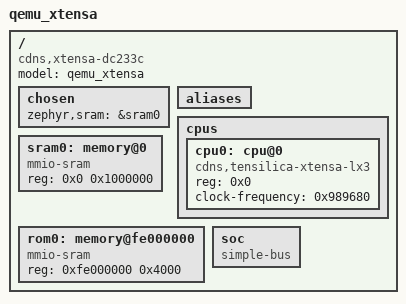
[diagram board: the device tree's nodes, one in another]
/dts-v1/;

/* node '/' defined in zephyr/dts/common/skeleton.dtsi:9 */
/ {
	#address-cells = < 0x1 >;          /* in zephyr/dts/common/skeleton.dtsi:10 */
	#size-cells = < 0x1 >;             /* in zephyr/dts/common/skeleton.dtsi:11 */
	model = "qemu_xtensa";             /* in zephyr/boards/qemu/xtensa/qemu_xtensa_dc233c.dts:12 */
	compatible = "cdns,xtensa-dc233c"; /* in zephyr/boards/qemu/xtensa/qemu_xtensa_dc233c.dts:13 */

	/* node '/chosen' defined in zephyr/dts/common/skeleton.dtsi:13 */
	chosen {
		zephyr,sram = &sram0; /* in zephyr/boards/qemu/xtensa/qemu_xtensa_dc233c.dts:16 */
	};

	/* node '/aliases' defined in zephyr/dts/common/skeleton.dtsi:15 */
	aliases {
	};

	/* node '/cpus' defined in zephyr/dts/xtensa/dc233c.dtsi:10 */
	cpus {
		#address-cells = < 0x1 >; /* in zephyr/dts/xtensa/dc233c.dtsi:11 */
		#size-cells = < 0x0 >;    /* in zephyr/dts/xtensa/dc233c.dtsi:12 */

		/* node '/cpus/cpu@0' defined in zephyr/dts/xtensa/dc233c.dtsi:14 */
		cpu0: cpu@0 {
			device_type = "cpu";                      /* in zephyr/dts/xtensa/dc233c.dtsi:15 */
			compatible = "cdns,tensilica-xtensa-lx3"; /* in zephyr/dts/xtensa/dc233c.dtsi:16 */
			reg = < 0x0 >;                            /* in zephyr/dts/xtensa/dc233c.dtsi:17 */
			clock-frequency = < 0x989680 >;           /* in zephyr/boards/qemu/xtensa/qemu_xtensa_dc233c.dts:21 */
		};
	};

	/* node '/memory@0' defined in zephyr/dts/xtensa/dc233c.dtsi:25 */
	sram0: memory@0 {
		device_type = "memory";   /* in zephyr/dts/xtensa/dc233c.dtsi:26 */
		compatible = "mmio-sram"; /* in zephyr/dts/xtensa/dc233c.dtsi:27 */
		reg = < 0x0 0x1000000 >;  /* in zephyr/dts/xtensa/dc233c.dtsi:28 */
	};

	/* node '/memory@fe000000' defined in zephyr/dts/xtensa/dc233c.dtsi:35 */
	rom0: memory@fe000000 {
		device_type = "memory";      /* in zephyr/dts/xtensa/dc233c.dtsi:36 */
		compatible = "mmio-sram";    /* in zephyr/dts/xtensa/dc233c.dtsi:37 */
		reg = < 0xfe000000 0x4000 >; /* in zephyr/dts/xtensa/dc233c.dtsi:38 */
	};

	/* node '/soc' defined in zephyr/dts/xtensa/dc233c.dtsi:41 */
	soc {
		#address-cells = < 0x1 >;  /* in zephyr/dts/xtensa/dc233c.dtsi:42 */
		#size-cells = < 0x1 >;     /* in zephyr/dts/xtensa/dc233c.dtsi:43 */
		compatible = "simple-bus"; /* in zephyr/dts/xtensa/dc233c.dtsi:44 */
		ranges;                    /* in zephyr/dts/xtensa/dc233c.dtsi:45 */
	};
};
